# Z32F3841 register map
Vendor: Zilog, Inc; File version: 1.0.1
CPU: CM3 r2p0, little endian, no MPU, no FPU, 3 interrupt priority bits
Registers are 32-bit, read-write, reset 0x0 unless marked. A register's access mark holds for its fields unless they carry their own. Offsets are from the block's base; [hi:lo] are bit positions; {n}, {i} and the like mark numbered series; 'fields as' and 'values as' point back to an identical list.

## MP0 — MOTOR PULSE-WIDTH-MODULATOR
Base 0x40004000
Same registers: MP1 0x40005000
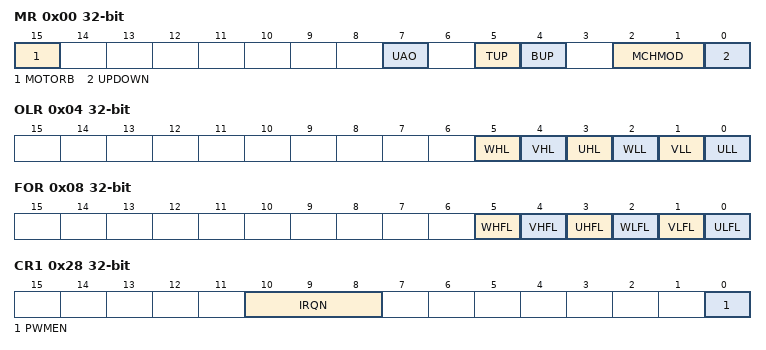
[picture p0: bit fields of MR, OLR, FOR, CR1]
0x00 MR — MPWM Mode Register
  [15] MOTORB — Motor Bit
  [7] UAO — Update timing
  [5] TUP — period, duty values updated at period match
  [4] BUP — period duty update at Bottom match
  [2:1] MCHMOD — Motor control channel mode
  [0] UPDOWN — PWM counter mode
0x04 OLR — MPWM Output Level Register
  [5] WHL — W High level
  [4] VHL — V High Level
  [3] UHL — U High Level
  [2] WLL — W Low Level
  [1] VLL — V Low Level
  [0] ULL — U Low Level
0x08 FOR — MPWM Forced Output Control Register
  [5] WHFL — W High Forced Level
  [4] VHFL — V High Forced Level
  [3] UHFL — U High Forced Level
  [2] WLFL — W Low Forced Level
  [1] VLFL — V Low Forced Level
  [0] ULFL — U Low Forced Level
0x0C PRD reset 0x2 — MPWM Period Register
  [15:0] PERIOD — PWM period
0x10 DUH reset 0x1 — MPWM Duty UH Register
  [15:0] DUTY — duty of UH output
0x14 DVH reset 0x1 — MPWM Duty VH Register
  [15:0] DUTY — duty of VH data
0x18 DWH reset 0x1 — MPWM Duty WH Register
  [15:0] DUTY — duty of WH output
0x1C DUL reset 0x1 — MPWM Duty UL Register
  [15:0] DUTY — duty of UL output
0x20 DVL reset 0x1 — MPWM Duty UL Register
  [15:0] DUTY — duty of VL output
0x24 DWL reset 0x1 — MPWM Duty WL Register
  [15:0] DUTY — duty of WL output
0x28 CR1 — MPWM Control Register 1
  [10:8] IRQN — IRQ interval Number
  [0] PWMEN — PWM enable
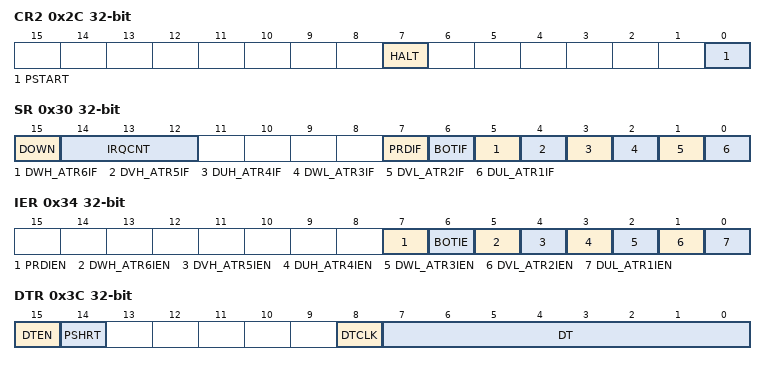
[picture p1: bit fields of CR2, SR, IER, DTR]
0x2C CR2 — MPWM Control Register 2
  [7] HALT — PWM HALT
  [0] PSTART — PWM start
0x30 SR — MPWM Status Register
  [15] DOWN — PWM count up/down
  [14:12] IRQCNT — PWM count number of period match
  [7] PRDIF — PWM period interrupt flag
  [6] BOTIF — PWM bottom interrupt flag
  [5] DWH_ATR6IF — duty WH/ATR6 interrupt flag
  [4] DVH_ATR5IF — duty VH/ATR5 interrupt flag
  [3] DUH_ATR4IF — duty UH/ATR4 interrupt flag
  [2] DWL_ATR3IF — duty WL/ATR3 interrupt flag
  [1] DVL_ATR2IF — duty VL/ATR2 interrupt flag
  [0] DUL_ATR1IF — duty UL/ATR1 interrupt flag
0x34 IER — MPWM Interrupt Enable Register
  [7] PRDIEN — Period interrupt enable
  [6] BOTIE — bottom interrupt enable
  [5] DWH_ATR6IEN — duty WH/ATR6 interrupt enable
  [4] DVH_ATR5IEN — duty VL/ATR5 interrupt enable
  [3] DUH_ATR4IEN — duty UH/ATR4 interrupt enable
  [2] DWL_ATR3IEN — duty WL/ATR3 interrupt enable
  [1] DVL_ATR2IEN — duty VL/ATR2 interrupt enable
  [0] DUL_ATR1IEN — duty UL/ATR1 interrupt enable
0x38 CNT — MPWM Counter Register
  [15:0] CNT — pwm counter value
0x3C DTR — MPWM Dead Time Register
  [15] DTEN — dead time Enable
  [14] PSHRT — Protect Short condition
  [8] DTCLK — dead time clk select
  [7:0] DT — dead time value
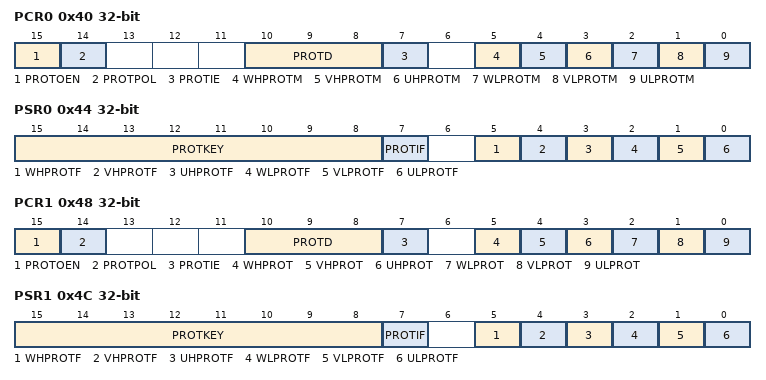
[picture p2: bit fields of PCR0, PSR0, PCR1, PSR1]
0x40 PCR0 — MPWM Protection control Register (PRTIN pin)
  [15] PROTOEN — Enable Protection Input 0 pin
  [14] PROTPOL — Input 0 Polarity
  [10:8] PROTD — Input 0 Debounce
  [7] PROTIE — Protection Interrupt Enable
  [5] WHPROTM — WH protection output
  [4] VHPROTM — VH protection output
  [3] UHPROTM — UH protection output
  [2] WLPROTM — WL protection output
  [1] VLPROTM — VL protection output
  [0] ULPROTM — UL protection output
0x44 PSR0 — MPWM Protection Status Register (PRTIN pin)
  [15:8] PROTKEY — lock safety pattern to set or reset protection
  [7] PROTIF — Protection Interrupt status
  [5] WHPROTF — WH Protection Flag status
  [4] VHPROTF — VH Protection Flag status
  [3] UHPROTF — UH Protection Flag status
  [2] WLPROTF — WL Protection Flag status
  [1] VLPROTF — VL Protection Flag status
  [0] ULPROTF — UL Protection Flag status
0x48 PCR1 — MPWM Protection control Register (OVIN pin)
  [15] PROTOEN — Enable Protection Input 0 pin
  [14] PROTPOL — Input 0 Polarity
  [10:8] PROTD — Input 0 Debounce
  [7] PROTIE — Protection Interrupt Enable
  [5] WHPROT — WH protection output
  [4] VHPROT — VH protection output
  [3] UHPROT — UH protection output
  [2] WLPROT — WL protection output
  [1] VLPROT — VL protection output
  [0] ULPROT — UL protection output
0x4C PSR1 — MPWM Protection Status Register (OVIN pin)
  fields as PSR0
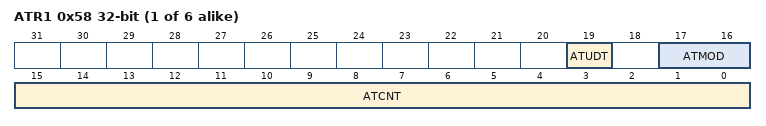
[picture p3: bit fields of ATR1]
{0x54+4i} ATR{i} (i=1..6) — MPWMn ADC Trigger Counter {i} Register
  [19] ATUDT — Trigger register update mode
  [17:16] ATMOD — ADC Trigger mode register
  [15:0] ATCNT — ADC Trigger counter
